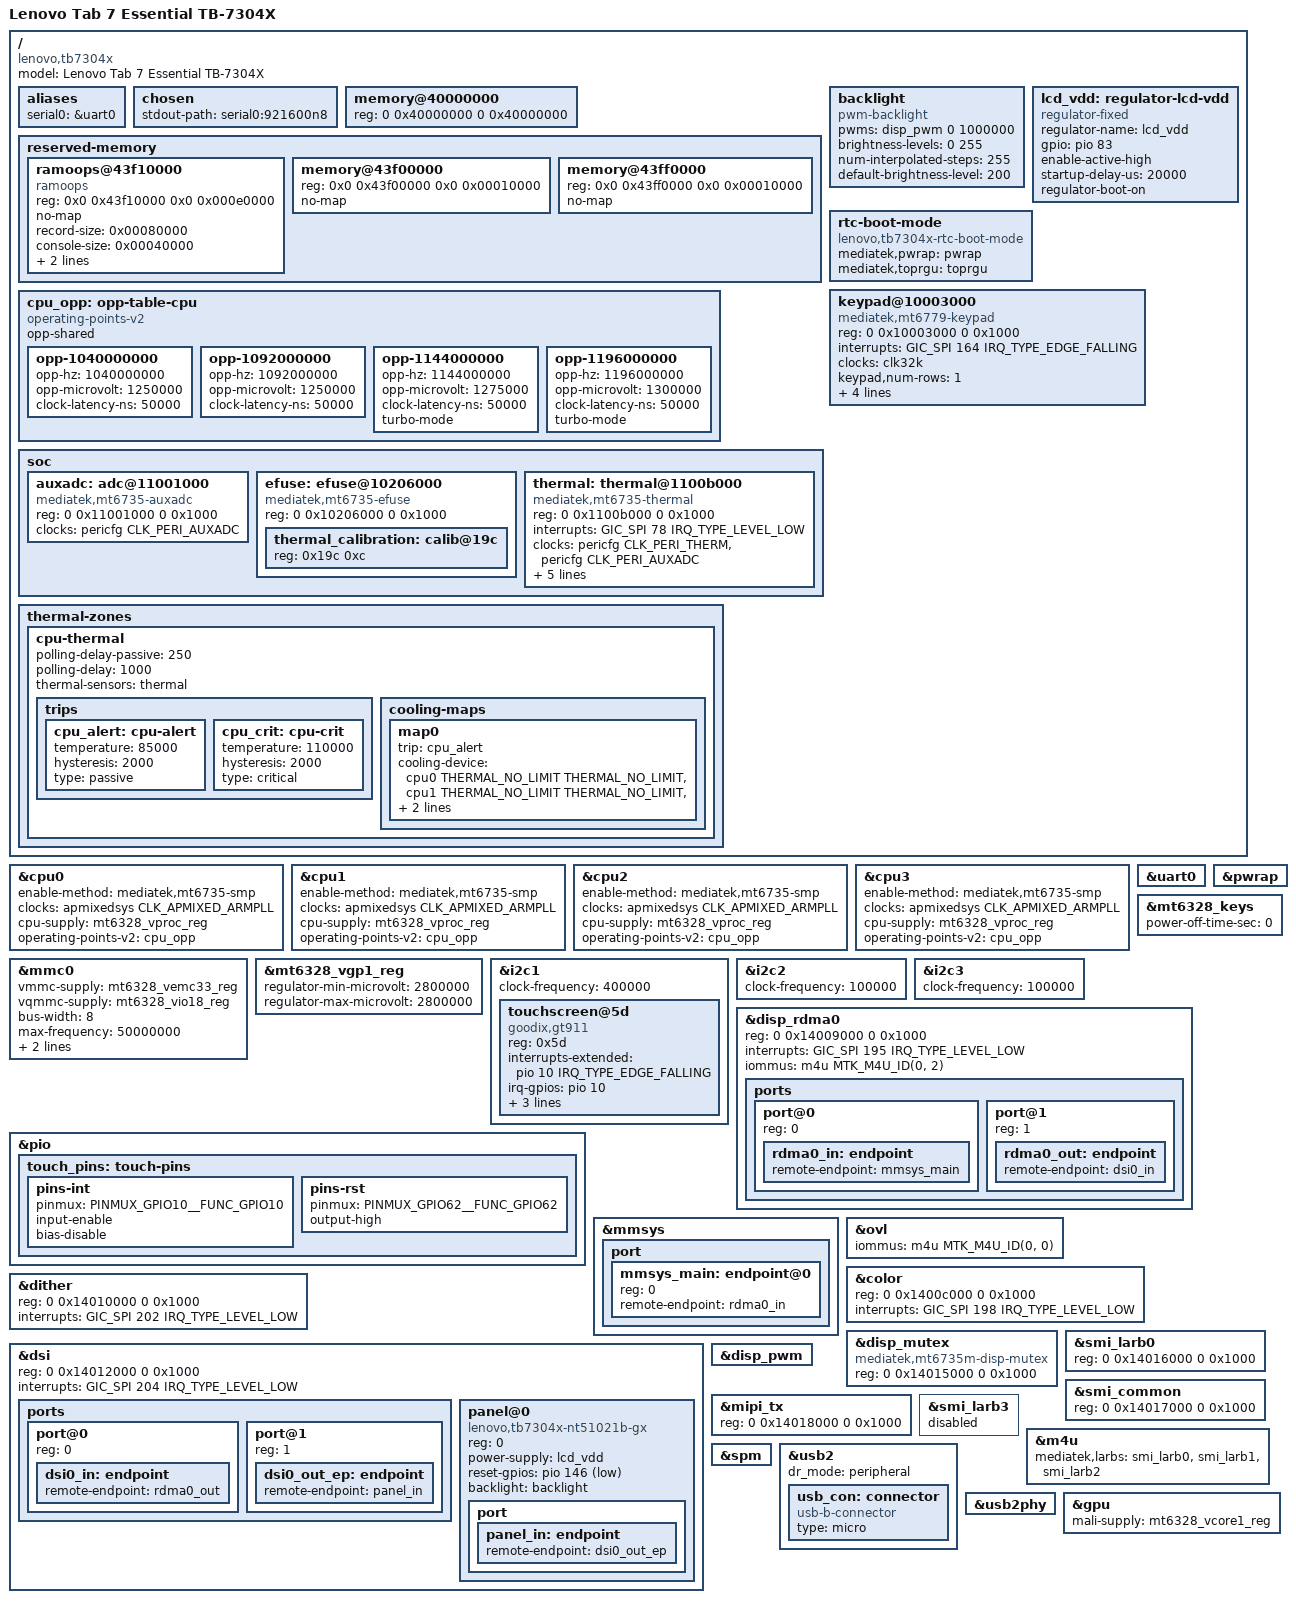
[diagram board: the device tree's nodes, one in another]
// SPDX-License-Identifier: BSD-3-Clause
/*
 * Lenovo Tab 7 Essential TB-7304X (MT6737M, 1 GB, 600x1024 DSI panel).
 * Minimal bring-up DTS adapted from mt6735p-doogee-x5pro.dts (MT6735P, same
 * "mt6735m" pinctrl/pwrap variant) and the stock 3.18 DTB extracted from boot.img.
 *
 * Goal: boot to an initramfs with USB gadget + a simple-framebuffer on the
 * display LK left running (registered by drivers/soc/mediatek/mtk-lk-fb.c from
 * /chosen "atag,videolfb" + the OVL0 registers). No panel/touch/WiFi/GPU yet.
 */

/dts-v1/;

#include "mt6735m.dtsi"
#include "mt6328.dtsi"
#include <dt-bindings/gpio/gpio.h>
#include <dt-bindings/input/input.h>
#include <dt-bindings/thermal/thermal.h>

/ {
	model = "Lenovo Tab 7 Essential TB-7304X";
	compatible = "lenovo,tb7304x", "mediatek,mt6737m", "mediatek,mt6735";

	aliases {
		serial0 = &uart0;
	};

	chosen {
		#address-cells = <2>;
		#size-cells = <2>;
		ranges;
		/* LK overwrites bootargs with the boot.img cmdline + its own additions */
		stdout-path = "serial0:921600n8";
	};

	/* LK rewrites this from its mblock table (1 GB minus its own reservations) */
	memory@40000000 {
		device_type = "memory";
		reg = <0 0x40000000 0 0x40000000>;
	};

	reserved-memory {
		/* same place the stock kernel uses for pstore ("mediatek,pstore") */
		ramoops@43f10000 {
			compatible = "ramoops";
			reg = <0x0 0x43f10000 0x0 0x000e0000>;
			no-map;

			record-size = <0x00080000>;
			console-size = <0x00040000>;
			ftrace-size = <0x00000000>;
			pmsg-size = <0x00010000>;
		};

		/* MTK ram_console + minirdump areas used by LK/stock kernel: leave untouched */
		memory@43f00000 {
			reg = <0x0 0x43f00000 0x0 0x00010000>;
			no-map;
		};

		memory@43ff0000 {
			reg = <0x0 0x43ff0000 0x0 0x00010000>;
			no-map;
		};
	};

	/*
	 * Volume keys sit on the SoC keypad matrix (stock: keypad@10003000, kpd-hw-init-map
	 * index 0 = KEY_VOLUMEUP, 1 = KEY_VOLUMEDOWN, single-key mode -> row 0, cols 0/1).
	 * mt6779-keypad uses the same MEM/DEBOUNCE/SEL register layout. Not in mt6735.dtsi.
	 */
	/*
	 * Backlight: the display PWM (0x1100e000), which LK leaves at 100 % (CON_1 = 0x03ff03ff). Its output pin
	 * (probably GPIO69) is left muxed by LK.
	 */
	backlight: backlight {
		compatible = "pwm-backlight";
		pwms = <&disp_pwm 0 1000000>;
		brightness-levels = <0 255>;
		num-interpolated-steps = <255>;
		default-brightness-level = <200>;
	};

	/* Panel logic supply, switched by GPIO83 (stock gpio_lcd_pwr); LK leaves it on */
	lcd_vdd: regulator-lcd-vdd {
		compatible = "regulator-fixed";
		regulator-name = "lcd_vdd";
		gpio = <&pio 83 GPIO_ACTIVE_HIGH>;
		enable-active-high;
		startup-delay-us = <20000>;
		regulator-boot-on;
	};

	/*
	 * `echo bootloader|recovery|normal > /sys/devices/platform/rtc-boot-mode/next_boot`: LK's next boot target.
	 * Also the power-off handler (PMIC RTC BBPU, or a TOPRGU reset into LK's power-off charging on a charger).
	 */
	rtc-boot-mode {
		compatible = "lenovo,tb7304x-rtc-boot-mode";
		mediatek,pwrap = <&pwrap>;
		mediatek,toprgu = <&toprgu>;
	};

	keypad@10003000 {
		compatible = "mediatek,mt6779-keypad";
		reg = <0 0x10003000 0 0x1000>;
		interrupts = <GIC_SPI 164 IRQ_TYPE_EDGE_FALLING>;
		clocks = <&clk32k>;
		clock-names = "kpd";
		keypad,num-rows = <1>;
		keypad,num-columns = <2>;
		debounce-delay-ms = <32>;
		linux,keymap = <MATRIX_KEY(0, 0, KEY_VOLUMEUP)
				MATRIX_KEY(0, 1, KEY_VOLUMEDOWN)>;
	};
};

/*
 * Secondary CPUs: plain PSCI CPU_ON does not power the core on with the stock ATF (that is the
 * "firmware issue" noted on the Doogee X5 Pro). The stock kernel's "mt-boot" does PSCI CPU_ON and
 * then the SPM MTCMOS power-on itself; arch/arm64/kernel/smp_mt6735.c does the same.
 */
&cpu0 { enable-method = "mediatek,mt6735-smp"; #cooling-cells = <2>; clocks = <&apmixedsys CLK_APMIXED_ARMPLL>; cpu-supply = <&mt6328_vproc_reg>; operating-points-v2 = <&cpu_opp>; };
&cpu1 { enable-method = "mediatek,mt6735-smp"; #cooling-cells = <2>; clocks = <&apmixedsys CLK_APMIXED_ARMPLL>; cpu-supply = <&mt6328_vproc_reg>; operating-points-v2 = <&cpu_opp>; };
&cpu2 { enable-method = "mediatek,mt6735-smp"; #cooling-cells = <2>; clocks = <&apmixedsys CLK_APMIXED_ARMPLL>; cpu-supply = <&mt6328_vproc_reg>; operating-points-v2 = <&cpu_opp>; };
&cpu3 { enable-method = "mediatek,mt6735-smp"; #cooling-cells = <2>; clocks = <&apmixedsys CLK_APMIXED_ARMPLL>; cpu-supply = <&mt6328_vproc_reg>; operating-points-v2 = <&cpu_opp>; };

/*
 * CPU DVFS (cpufreq-dt): ARMPLL straight, VPROC from the MT6328 (patches/0005 fixes its vsel register).
 * Voltages from the stock kernel's MT6737M table (1092/988/858/793/637 MHz at 1.25/1.21875/1.1875/1.15/1.10 V,
 * found in the stock Image), without PTP-OD's per-chip undervolt.
 *
 * Performance-only: every OPP is at ARMPLL post-divider /1 (VCO = CPU clock, >= 1 GHz). Measured by poking
 * ARMPLL_CON1 from userspace (kernel #17): pcw changes are safe at any time; /2 -> /1 with the VCO moved first
 * (patches/0007) worked; /1 -> /2 hung the SoC; and the PLL ignores pcw writes for a VCO above ~2 GHz, so 1092 MHz
 * cannot be had at /2. Mainline has no CPU clock mux to park on (the stock kernel switches to MAINPLL around
 * post-divider changes), so the table never goes back below /1: the only post-divider change is cpufreq's first
 * switch away from LK's 793 MHz (/2), upwards. The cost is no idle below 1040 MHz.
 * 1144 and 1196 MHz are overclocks, turbo-mode (boost; rootfs local.d/tb-cpu.start turns it on). 1196 MHz is the
 * highest pcw the ARMPLL accepted (0xb8000-0xba000; writes above are dropped), and passed 30 s of a 4-core
 * NEON/scalar cross-check at 1.30 V (kernel #20, poked by hand). +25 / +50 mV over the stock 1.25 V top.
 * VSRAM (LDO, 1.35 V from LK) stays above every VPROC level here.
 */
/ {
	cpu_opp: opp-table-cpu {
		compatible = "operating-points-v2";
		opp-shared;

		opp-1040000000 {
			opp-hz = /bits/ 64 <1040000000>;
			opp-microvolt = <1250000>;
			clock-latency-ns = <50000>;
		};
		opp-1092000000 {
			opp-hz = /bits/ 64 <1092000000>;
			opp-microvolt = <1250000>;
			clock-latency-ns = <50000>;
		};
		opp-1144000000 {
			opp-hz = /bits/ 64 <1144000000>;
			opp-microvolt = <1275000>;
			clock-latency-ns = <50000>;
			turbo-mode;
		};
		opp-1196000000 {
			opp-hz = /bits/ 64 <1196000000>;
			opp-microvolt = <1300000>;
			clock-latency-ns = <50000>;
			turbo-mode;
		};
	};
};

&uart0 {
	status = "okay";
};

/* eMMC: probed read-only by userspace convention (init never mounts it). */
&mmc0 {
	status = "okay";

	vmmc-supply = <&mt6328_vemc33_reg>;
	vqmmc-supply = <&mt6328_vio18_reg>;

	bus-width = <8>;
	max-frequency = <50000000>;	/* conservative: no HS200/HS400 tuning data yet */
	cap-mmc-highspeed;
	non-removable;
};

&pwrap {
	status = "okay";
};

/*
 * Power key (and the PMIC "home" input, unused on this tablet). long-press-mode 1 (from mt6328.dtsi): holding
 * power resets the PMIC in hardware, whatever the kernel is doing (needs patches/0010). power-off-time-sec is
 * the raw PWRKEY_RST_TD field (bits 13:12), not seconds; 0 is the reset default. Time each value on the tablet.
 */
&mt6328_keys {
	power-off-time-sec = <0>;
	status = "okay";
};

/* Touch supply: stock "vtouch-supply" = VGP1, set to 2.8 V by the stock tpd driver */
&mt6328_vgp1_reg {
	regulator-min-microvolt = <2800000>;
	regulator-max-microvolt = <2800000>;
};

/*
 * Touch: stock i2c1 (11008000) cap_touch@5d = Goodix GT9xx ("gt9xx 1-005d" in the stock log).
 * Stock pinctrl: EINT/INT on GPIO10 (eint 10, falling), reset on GPIO62.
 */
&i2c1 {
	status = "okay";
	clock-frequency = <400000>;

	touchscreen@5d {
		compatible = "goodix,gt911";
		reg = <0x5d>;
		interrupts-extended = <&pio 10 IRQ_TYPE_EDGE_FALLING>;
		irq-gpios = <&pio 10 GPIO_ACTIVE_HIGH>;
		reset-gpios = <&pio 62 GPIO_ACTIVE_HIGH>;
		AVDD28-supply = <&mt6328_vgp1_reg>;
		pinctrl-names = "default";
		pinctrl-0 = <&touch_pins>;
	};
};

/*
 * Sensors (stock: MC3433 accelerometer @0x4c, or a BMA2xx @0x18 as second source; SX9310 @0x28 and A96T316 @0x20
 * SAR sensors). No device nodes yet: enabled for i2c-dev probing (docs/mainline/research-power.md).
 */
&i2c2 {
	status = "okay";
	clock-frequency = <100000>;
};

/* SM5414 charger @0x49. No driver yet; LK programs and enables it on every boot. Bus enabled for i2c-dev reads. */
&i2c3 {
	status = "okay";
	clock-frequency = <100000>;
};

&pio {
	touch_pins: touch-pins {
		pins-int {
			pinmux = <PINMUX_GPIO10__FUNC_GPIO10>;
			input-enable;
			bias-disable;
		};

		pins-rst {
			pinmux = <PINMUX_GPIO62__FUNC_GPIO62>;
			output-high;
		};
	};
};

/*
 * D2 MMSYS (MT6735M/MT6737M): unlike the D1 layout in mt6735.dtsi there is an (absent) OVL1 slot at 0x14008000,
 * so every block after OVL0 sits 0x1000 higher and its SPI is one higher. Confirmed on this tablet by reading the
 * registers LK left running (docs/mainline/STATUS.md, "Display step 0"). Node names keep the D1 unit addresses.
 */
&disp_rdma0 {
	reg = <0 0x14009000 0 0x1000>;
	interrupts = <GIC_SPI 195 IRQ_TYPE_LEVEL_LOW>;
	iommus = <&m4u MTK_M4U_ID(0, 2)>;	/* D2 larb0: OVL0 0/1, RDMA0 2, WDMA0 3 */
	status = "okay";

	/* Minimal pipeline: RDMA0 reads the framebuffer itself and feeds DSI0 (no OVL/COLOR/.../DITHER yet) */
	ports {
		#address-cells = <1>;
		#size-cells = <0>;

		port@0 {
			reg = <0>;
			rdma0_in: endpoint {
				remote-endpoint = <&mmsys_main>;
			};
		};

		port@1 {
			reg = <1>;
			rdma0_out: endpoint {
				remote-endpoint = <&dsi0_in>;
			};
		};
	};
};

&mmsys {
	port {
		#address-cells = <1>;
		#size-cells = <0>;

		mmsys_main: endpoint@0 {
			reg = <0>;	/* CRTC_MAIN */
			remote-endpoint = <&rdma0_in>;
		};
	};
};

&ovl {
	iommus = <&m4u MTK_M4U_ID(0, 0)>;
};

&color {
	reg = <0 0x1400c000 0 0x1000>;
	interrupts = <GIC_SPI 198 IRQ_TYPE_LEVEL_LOW>;
};

&dither {
	reg = <0 0x14010000 0 0x1000>;
	interrupts = <GIC_SPI 202 IRQ_TYPE_LEVEL_LOW>;
};

&dsi {
	reg = <0 0x14012000 0 0x1000>;
	interrupts = <GIC_SPI 204 IRQ_TYPE_LEVEL_LOW>;
	status = "okay";

	/delete-node/ port;

	ports {
		#address-cells = <1>;
		#size-cells = <0>;

		port@0 {
			reg = <0>;
			dsi0_in: endpoint {
				remote-endpoint = <&rdma0_out>;
			};
		};

		port@1 {
			reg = <1>;
			dsi0_out_ep: endpoint {
				remote-endpoint = <&panel_in>;
			};
		};
	};

	/* NT51021B, "nt51021b_dsi_vdo_gx" in LK's atag */
	panel@0 {
		compatible = "lenovo,tb7304x-nt51021b-gx";
		reg = <0>;
		power-supply = <&lcd_vdd>;
		reset-gpios = <&pio 146 GPIO_ACTIVE_LOW>;
		backlight = <&backlight>;

		port {
			panel_in: endpoint {
				remote-endpoint = <&dsi0_out_ep>;
			};
		};
	};
};

&disp_mutex {
	compatible = "mediatek,mt6735m-disp-mutex", "mediatek,mt6735-disp-mutex";
	reg = <0 0x14015000 0 0x1000>;
	status = "okay";
};

&smi_larb0 {
	reg = <0 0x14016000 0 0x1000>;
};

&smi_common {
	reg = <0 0x14017000 0 0x1000>;
};

&disp_pwm {
	status = "okay";
};

&mipi_tx {
	reg = <0 0x14018000 0 0x1000>;
	status = "okay";
};

/* D2 has three larbs; larb3 (VENC) is in the VEN domain deleted below, so it never probes and the M4U would wait. */
&smi_larb3 {
	status = "disabled";
};

&m4u {
	mediatek,larbs = <&smi_larb0>, <&smi_larb1>, <&smi_larb2>;
};

&spm {
	/* as on Doogee X5 Pro: VEN domain does not come up */
	/delete-node/ power-domain@MT6735_POWER_DOMAIN_VEN;
};

&usb2 {
	status = "okay";
	dr_mode = "peripheral";

	usb_con: connector {
		compatible = "usb-b-connector";
		type = "micro";
	};
};

&usb2phy {
	status = "okay";
};

/*
 * Mali-T720 MP1 (Panfrost). Power domain, mfgcfg clock and resets come from mt6735.dtsi; the supply is VCORE1
 * as on the Galaxy Grand Prime+ (mt6737t-samsung-grandpplte.dts). No OPP table yet: the GPU runs at whatever
 * mfg_sel LK left.
 */
&gpu {
	status = "okay";
	mali-supply = <&mt6328_vcore1_reg>;
};

/*
 * SoC thermal (patches/0009): the MT8173-type thermal controller reads TS_MCU3 (CPU), TS_MCU1 (SoC+GPU) and TS_MCU2
 * (LTE) through AUXADC channel 11, calibrated from efuse 0x19c..0x1a7 (same fields as MT8173). The zone reports the
 * hottest bank. CPU cooling can only step down to 1040 MHz (ARMPLL /1 only, see the OPP table): with the overclock
 * on, 85 °C drops the boost OPPs first.
 */
/ {
	soc {
		auxadc: adc@11001000 {
			compatible = "mediatek,mt6735-auxadc", "mediatek,mt8173-auxadc";
			reg = <0 0x11001000 0 0x1000>;
			clocks = <&pericfg CLK_PERI_AUXADC>;
			clock-names = "main";
			#io-channel-cells = <1>;
		};

		efuse: efuse@10206000 {
			compatible = "mediatek,mt6735-efuse", "mediatek,efuse";
			reg = <0 0x10206000 0 0x1000>;
			#address-cells = <1>;
			#size-cells = <1>;

			thermal_calibration: calib@19c {
				reg = <0x19c 0xc>;
			};
		};

		thermal: thermal@1100b000 {
			compatible = "mediatek,mt6735-thermal";
			reg = <0 0x1100b000 0 0x1000>;
			interrupts = <GIC_SPI 78 IRQ_TYPE_LEVEL_LOW>;
			clocks = <&pericfg CLK_PERI_THERM>, <&pericfg CLK_PERI_AUXADC>;
			clock-names = "therm", "auxadc";
			resets = <&pericfg MT6735_PERI_RST0_THERM>;
			mediatek,auxadc = <&auxadc>;
			mediatek,apmixedsys = <&apmixedsys>;
			nvmem-cells = <&thermal_calibration>;
			nvmem-cell-names = "calibration-data";
			#thermal-sensor-cells = <0>;
		};
	};

	thermal-zones {
		cpu-thermal {
			polling-delay-passive = <250>;
			polling-delay = <1000>;
			thermal-sensors = <&thermal>;

			trips {
				cpu_alert: cpu-alert {
					temperature = <85000>;
					hysteresis = <2000>;
					type = "passive";
				};
				cpu_crit: cpu-crit {
					temperature = <110000>;
					hysteresis = <2000>;
					type = "critical";
				};
			};

			cooling-maps {
				map0 {
					trip = <&cpu_alert>;
					cooling-device = <&cpu0 THERMAL_NO_LIMIT THERMAL_NO_LIMIT>,
							 <&cpu1 THERMAL_NO_LIMIT THERMAL_NO_LIMIT>,
							 <&cpu2 THERMAL_NO_LIMIT THERMAL_NO_LIMIT>,
							 <&cpu3 THERMAL_NO_LIMIT THERMAL_NO_LIMIT>;
				};
			};
		};
	};
};
